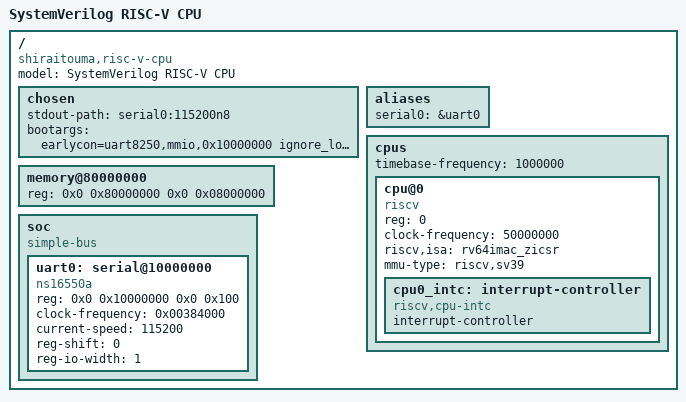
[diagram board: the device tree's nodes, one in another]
/dts-v1/;

/ {
	#address-cells = <2>;
	#size-cells = <2>;
	compatible = "shiraitouma,risc-v-cpu";
	model = "SystemVerilog RISC-V CPU";

	chosen {
		stdout-path = "serial0:115200n8";
		bootargs = "earlycon=uart8250,mmio,0x10000000 ignore_loglevel";
	};

	aliases {
		serial0 = &uart0;
	};

	cpus {
		#address-cells = <1>;
		#size-cells = <0>;
		timebase-frequency = <1000000>;

		cpu@0 {
			device_type = "cpu";
			reg = <0>;
			status = "okay";
			compatible = "riscv";
			clock-frequency = <50000000>;
			riscv,isa = "rv64imac_zicsr";
			mmu-type = "riscv,sv39";

			cpu0_intc: interrupt-controller {
				#interrupt-cells = <1>;
				interrupt-controller;
				compatible = "riscv,cpu-intc";
			};
		};
	};

	memory@80000000 {
		device_type = "memory";
		reg = <0x0 0x80000000 0x0 0x08000000>;
	};

	soc {
		#address-cells = <2>;
		#size-cells = <2>;
		compatible = "simple-bus";
		ranges;

		uart0: serial@10000000 {
			compatible = "ns16550a";
			reg = <0x0 0x10000000 0x0 0x100>;
			clock-frequency = <0x00384000>;
			current-speed = <115200>;
			reg-shift = <0>;
			reg-io-width = <1>;
			status = "okay";
		};
	};
};
